# rCSL_eqep_001 register map
Vendor: Texas Instruments
Peripheral module from a debugger description file (folder OMAPL138_C6748).
Registers are 16-bit, read-write, reset 0x0 unless marked. A register's access mark holds for its fields unless they carry their own. Offsets are as the file gives them; lines under a group give offsets from that group; [hi:lo] are bit positions; {n}, {i} and the like mark numbered series; 'fields as' and 'values as' point back to an identical list; <NAME> marks a mode.

## EQEP — Enhanced quadrature encoder pulse module. Used to directly interface to a linear or rotary incremental encoder to get position, direction, and speed information.
0x00 QPOSCNT 32-bit — Position counter
  [31:0] QPOSCNT — 32-bit position counter; counts up/down on each QEP pulse based on direction
0x04 QPOSINIT 32-bit — Initialization position count
  [31:0] QPOSINIT — Position value used to init the position counter
0x08 QPOSMAX 32-bit — Maximum position count
  [31:0] QPOSMAX — Maximum positon counter value
0x0C QPOSCMP 32-bit — Position-compare
  [31:0] QPOSCMP — Position-compare value
0x10 QPOSILAT 32-bit ro — Index position latch
  [31:0] QPOSILAT — Position counter value is latched into this reg on an index event as defined by QEPCTL[IEL].
0x14 QPOSSLAT 32-bit ro — Strobe position latch
  [31:0] QPOSSLAT — Position counter value is latched into this reg on a strobe event as defined by QEPCTL[SEL].
0x18 QPOSLAT 32-bit ro — Position latch
  [31:0] QPOSLAT — Position counter value is latched into this reg on unit timeout event.
0x1C QUTMR 32-bit — Unit timer
  [31:0] QUTMR — Timebase for unit time event generation.
0x20 QUPRD 32-bit — Unit period register
  [31:0] QUPRD — Period count for unit timer to generate periodic unit time events.
0x24 QWDTMR — Watchdog timer
  [31:0] QWDTMR — Timebase for watchdog.
0x26 QWDPRD — Watchdog period register
  [31:0] QWDPRD — Contains timeout count for the watchdog timer.
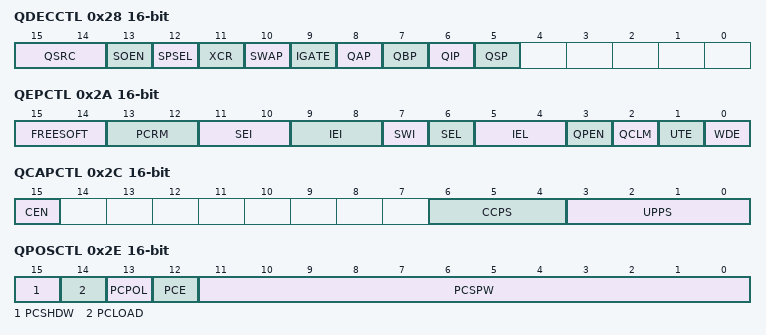
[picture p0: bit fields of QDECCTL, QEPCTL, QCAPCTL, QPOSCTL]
0x28 QDECCTL access not given — Decoder control
  [15:14] QSRC rw — Position counter source selection
    0=QUADCOUNT; 1=DIRCOUNT; 2=UPCOUNT; 3=DOWNCOUNT
  [13] SOEN rw — Sync output-enable
    0=DISABLE; 1=ENABLE
  [12] SPSEL rw — Sync output pin selection
    0=INDEX; 1=STROBE
  [11] XCR rw — External clock rate
    0=2XRESOLUTION; 1=1XRESOLUTION
  [10] SWAP rw — Swap quadrature clock inputs
    0=NOSWAP; 1=SWAP
  [9] IGATE rw — Index pulse gating option
    0=DISABLE; 1=GATE
  [8] QAP rw — QEPA input polarity
    0=NOEFFECT; 1=NEGATEQEPA
  [7] QBP rw — QEPB input polarity
    0=NOEFFECT; 1=NEGATEQEPB
  [6] QIP rw — QEPI input polarity
    0=NOEFFECT; 1=NEGATEQEPI
  [5] QSP rw — QEPS input polarity
    0=NOEFFECT; 1=NEGATEQEPS
0x2A QEPCTL — Control
  [15:14] FREESOFT — Emulation control bits
    0=STOPNOW; 1=COUNTUNTIL; 2=IGNORE; 3=IGNORE1
  [13:12] PCRM — Position counter reset mode
    0=ONINDEX; 1=ONMAXPOS; 2=ON1STINDEX; 3=ONUTEVT
  [11:10] SEI — Strobe event initialization of position counter
    0=NOEFFECT; 1=NOEFFECT1; 2=ONREDGE; 3=ONFEDGE
  [9:8] IEI — Index event initialization of position counter
    0=NOEFFECT; 1=NOEFFECT1; 2=ONREDGE; 3=ONFEDGE
  [7] SWI — Software initialization of position counter
    0=NOEFFECT; 1=INIT
  [6] SEL — Strobe event latch of position counter
    0=ONREDGE; 1=ONFEDGE
  [5:4] IEL — Index event latch of position counter
    1=ONREDGE; 2=ONFEDGE; 3=SWINDEX
  [3] QPEN — Quadrature position counter enable/software reset
    0=SWRESET; 1=ENPOSCNT
  [2] QCLM — eQEP capture latch mode
    0=ONPOSCNT; 1=ONUTIMEOUT
  [1] UTE — eQEP unit timer enable
    0=DISABLE; 1=ENABLE
  [0] WDE — eQEP watchdog enable
    0=DISABLE; 1=ENABLE
0x2C QCAPCTL access not given — Capture control
  [15] CEN rw — Enable eQEP capture
    0=DISABLED; 1=ENABLED
  [6:4] CCPS rw — Capture timer clock prescaler; CAPCLK=
    0=SYSCLKOUTDIV1; 1=SYSCLKOUTDIV2; 2=SYSCLKOUTDIV4; 3=SYSCLKOUTDIV8; 4=SYSCLKOUTDIV16; 5=SYSCLKOUTDIV32; 6=SYSCLKOUTDIV64; 7=SYSCLKOUTDIV128
  [3:0] UPPS rw — Unit position event prescaler; UPEVNT=
0x2E QPOSCTL — Position-compare control
  [15] PCSHDW — Shadow enable
    0=DISABLED; 1=ENABLED
  [14] PCLOAD — Shadow load mode
    0=ONEQUALZERO; 1=ONEQUALQPOSCMP
  [13] PCPOL — Polarity of sync output
    0=ACTIVEHIGH; 1=ACTIVELOW
  [12] PCE — Enable/disable
    0=DISABLE; 1=ENABLE
  [11:0] PCSPW — Select-position-compare sync out pulse width
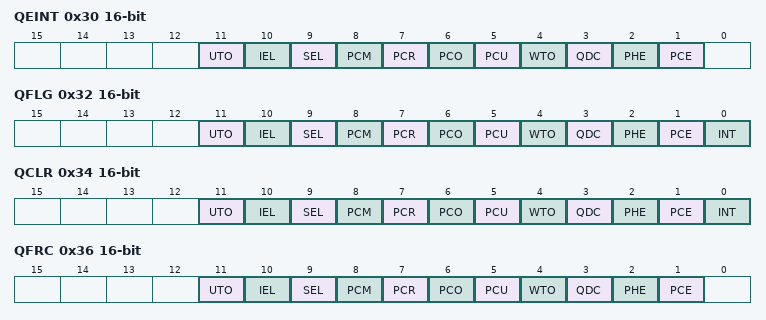
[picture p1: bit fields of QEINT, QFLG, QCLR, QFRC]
0x30 QEINT access not given — Interrupt enable
  [all] fields
    0=DISABLED; 1=ENABLED
  [11] UTO rw — Unit timeout interrupt enable
  [10] IEL rw — Index event latch interrupt enable
  [9] SEL rw — Strobe event latch interrupt enable
  [8] PCM rw — Position-compare match interrupt enable
  [7] PCR rw — Position-compare ready interrupt enable
  [6] PCO rw — Position counter overflow interrupt enable
  [5] PCU rw — Positon counter underflow interrupt enable
  [4] WTO rw — Watchdog timeout interrupt enable
  [3] QDC rw — Quadrature direction change interrupt enable
  [2] PHE rw — Quadrature phase error interrupt enable
  [1] PCE rw — Position counter error interrupt enable
0x32 QFLG access not given — Interrupt flag
  [all] fields
    0=NOINT; 1=INT
  [11] UTO ro — Unit timeout interrupt flag
  [10] IEL ro — Index event latch interrupt flag
  [9] SEL ro — Strobe event latch interrupt flag
  [8] PCM ro — Position-compare match interrupt flag
  [7] PCR ro — Position-compare ready interrupt flag
  [6] PCO ro — Position counter overflow interrupt flag
  [5] PCU ro — Positon counter underflow interrupt flag
  [4] WTO ro — Watchdog timeout interrupt flag
  [3] QDC ro — Quadrature direction change interrupt flag
  [2] PHE ro — Quadrature phase error interrupt flag
  [1] PCE ro — Position counter error interrupt flag
  [0] INT ro — Global interrupt status flag
0x34 QCLR access not given — Interrupt clear
  [all] fields
    0=NOEFFECT; 1=CLEAR
  [11] UTO rw — Clear unit timeout interrupt flag
  [10] IEL rw — Clear index event latch interrupt flag
  [9] SEL rw — Clear strobe event latch interrupt flag
  [8] PCM rw — Clear position-compare match interrupt flag
  [7] PCR rw — Clear position-compare ready interrupt flag
  [6] PCO rw — Clear position counter overflow interrupt flag
  [5] PCU rw — Clear positon counter underflow interrupt flag
  [4] WTO rw — Clear watchdog timeout interrupt flag
  [3] QDC rw — Clear quadrature direction change interrupt flag
  [2] PHE rw — Clear quadrature phase error interrupt flag
  [1] PCE rw — Clear position counter error interrupt flag
  [0] INT rw — Clear global interrupt status flag
0x36 QFRC access not given — Interrupt force
  [all] fields
    0=NOEFFECT; 1=FORCE
  [11] UTO rw — Force unit timeout interrupt flag
  [10] IEL rw — Force index event latch interrupt flag
  [9] SEL rw — Force strobe event latch interrupt flag
  [8] PCM rw — Force position-compare match interrupt flag
  [7] PCR rw — Force position-compare ready interrupt flag
  [6] PCO rw — Force position counter overflow interrupt flag
  [5] PCU rw — Force positon counter underflow interrupt flag
  [4] WTO rw — Force watchdog timeout interrupt flag
  [3] QDC rw — Force quadrature direction change interrupt flag
  [2] PHE rw — Force quadrature phase error interrupt flag
  [1] PCE rw — Force position counter error interrupt flag
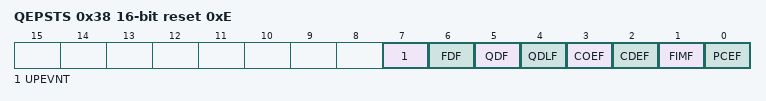
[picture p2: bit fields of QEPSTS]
0x38 QEPSTS access not given reset 0xE — Status
  [7] UPEVNT ro — Unit position event flag
    0=NOTDETECTED; 1=DETECTED
  [6] FDF ro — Direction on first index marker
    0=CNTRCLKWISE; 1=CLKWISE
  [5] QDF ro — Quadrature direction flag
    0=CNTRCLKWISE; 1=CLKWISE
  [4] QDLF ro — eQEP direction latch flag
    0=CNTRCLKWISE; 1=CLKWISE
  [3] COEF rw — Capture overflow error flag
    0=WRITEONETOCLEAR; 1=OVERFLOW
  [2] CDEF rw — Capture direction error flag
    0=WRITEONETOCLEAR; 1=DIRCHANGE
  [1] FIMF rw — First index marker flag
    0=WRITEONETOCLEAR; 1=FIRSTINDEXPULSE
  [0] PCEF ro — Positon counter error flag
    0=NOERROR; 1=ERROR
0x3A QCTMR — Capture timer
  [15:0] QCTMR — Timebase for edge capture unit
0x3C QCPRD — Capture period
  [15:0] QCPRD — Period count value bwteen last successive eQEP position events.
0x3E QCTMRLAT ro — Capture timer latch
  [15:0] QCTMRLAT — Capture timer value can be latched into this reg.
0x40 QCPRDLAT — Capture period latch
  [15:0] QCPDRLAT — eQEP capture period value can be latched into this reg
0x5C REVID 32-bit ro reset 0x44D31103 — Revision ID
  [31:0] REV
